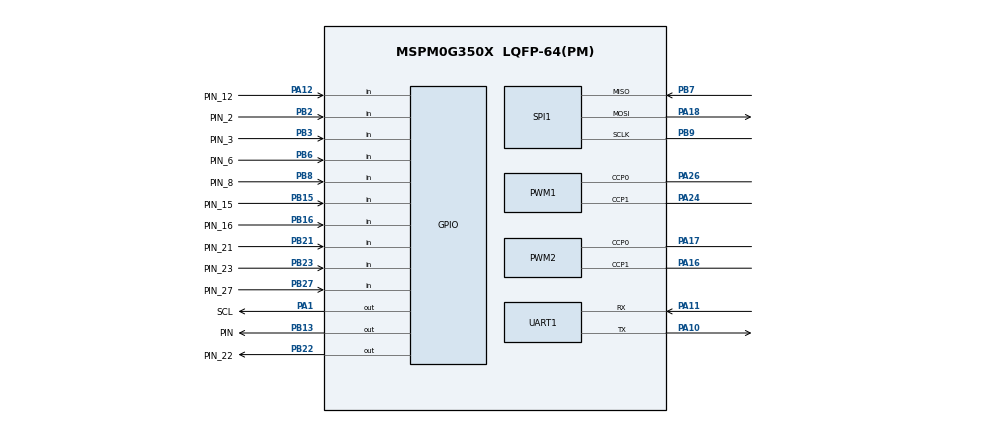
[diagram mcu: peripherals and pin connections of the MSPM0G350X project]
/**
 * @cliArgs --device "MSPM0G350X" --part "Default" --package "LQFP-64(PM)" --product "mspm0_sdk@2.02.00.05"
 * @versions {"tool":"1.21.1+3772"}
 */

/**
 * Import the modules used in this configuration.
 */
const GPIO   = scripting.addModule("/ti/driverlib/GPIO", {}, false);
const GPIO1  = GPIO.addInstance();
const GPIO2  = GPIO.addInstance();
const GPIO3  = GPIO.addInstance();
const GPIO4  = GPIO.addInstance();
const GPIO5  = GPIO.addInstance();
const GPIO6  = GPIO.addInstance();
const GPIO7  = GPIO.addInstance();
const GPIO8  = GPIO.addInstance();
const GPIO9  = GPIO.addInstance();
const GPIO10 = GPIO.addInstance();
const GPIO11 = GPIO.addInstance();
const GPIO12 = GPIO.addInstance();
const GPIO13 = GPIO.addInstance();
const PWM    = scripting.addModule("/ti/driverlib/PWM", {}, false);
const PWM1   = PWM.addInstance();
const PWM2   = PWM.addInstance();
const SPI    = scripting.addModule("/ti/driverlib/SPI", {}, false);
const SPI1   = SPI.addInstance();
const SYSCTL = scripting.addModule("/ti/driverlib/SYSCTL");
const TIMER  = scripting.addModule("/ti/driverlib/TIMER", {}, false);
const TIMER1 = TIMER.addInstance();
const UART   = scripting.addModule("/ti/driverlib/UART", {}, false);
const UART1  = UART.addInstance();

/**
 * Write custom configuration values to the imported modules.
 */
const gate7  = system.clockTree["MFCLKGATE"];
gate7.enable = true;

GPIO1.$name                              = "LED1";
GPIO1.port                               = "PORTB";
GPIO1.associatedPins[0].$name            = "PIN_22";
GPIO1.associatedPins[0].internalResistor = "PULL_DOWN";
GPIO1.associatedPins[0].assignedPin      = "22";
GPIO1.associatedPins[0].pin.$assign      = "PB22";

const Board = scripting.addModule("/ti/driverlib/Board", {}, false);

GPIO2.$name                              = "M0";
GPIO2.port                               = "PORTA";
GPIO2.associatedPins[0].direction        = "INPUT";
GPIO2.associatedPins[0].internalResistor = "PULL_DOWN";
GPIO2.associatedPins[0].$name            = "PIN_12";
GPIO2.associatedPins[0].assignedPin      = "12";
GPIO2.associatedPins[0].pin.$assign      = "PA12";

GPIO3.$name                              = "L1";
GPIO3.port                               = "PORTB";
GPIO3.associatedPins[0].direction        = "INPUT";
GPIO3.associatedPins[0].internalResistor = "PULL_DOWN";
GPIO3.associatedPins[0].$name            = "PIN_23";
GPIO3.associatedPins[0].assignedPin      = "23";
GPIO3.associatedPins[0].pin.$assign      = "PB23";

GPIO4.$name                              = "L2";
GPIO4.port                               = "PORTB";
GPIO4.associatedPins[0].direction        = "INPUT";
GPIO4.associatedPins[0].internalResistor = "PULL_DOWN";
GPIO4.associatedPins[0].$name            = "PIN_27";
GPIO4.associatedPins[0].assignedPin      = "27";
GPIO4.associatedPins[0].pin.$assign      = "PB27";

GPIO5.$name                              = "R1";
GPIO5.port                               = "PORTB";
GPIO5.associatedPins[0].direction        = "INPUT";
GPIO5.associatedPins[0].internalResistor = "PULL_DOWN";
GPIO5.associatedPins[0].$name            = "PIN_8";
GPIO5.associatedPins[0].assignedPin      = "8";
GPIO5.associatedPins[0].pin.$assign      = "PB8";

GPIO6.$name                              = "R2";
GPIO6.port                               = "PORTB";
GPIO6.associatedPins[0].direction        = "INPUT";
GPIO6.associatedPins[0].internalResistor = "PULL_DOWN";
GPIO6.associatedPins[0].$name            = "PIN_6";
GPIO6.associatedPins[0].assignedPin      = "6";
GPIO6.associatedPins[0].pin.$assign      = "PB6";

GPIO7.port                               = "PORTB";
GPIO7.$name                              = "KEY_4";
GPIO7.associatedPins[0].internalResistor = "PULL_UP";
GPIO7.associatedPins[0].direction        = "INPUT";
GPIO7.associatedPins[0].$name            = "PIN_3";
GPIO7.associatedPins[0].assignedPin      = "3";
GPIO7.associatedPins[0].pin.$assign      = "PB3";

GPIO8.port                               = "PORTB";
GPIO8.$name                              = "KEY_3";
GPIO8.associatedPins[0].internalResistor = "PULL_UP";
GPIO8.associatedPins[0].direction        = "INPUT";
GPIO8.associatedPins[0].$name            = "PIN_2";
GPIO8.associatedPins[0].assignedPin      = "2";
GPIO8.associatedPins[0].pin.$assign      = "PB2";

GPIO9.port                               = "PORTB";
GPIO9.$name                              = "KEY_2";
GPIO9.associatedPins[0].internalResistor = "PULL_UP";
GPIO9.associatedPins[0].direction        = "INPUT";
GPIO9.associatedPins[0].$name            = "PIN_16";
GPIO9.associatedPins[0].assignedPin      = "16";
GPIO9.associatedPins[0].pin.$assign      = "PB16";

GPIO10.port                               = "PORTB";
GPIO10.$name                              = "KEY_1";
GPIO10.associatedPins[0].direction        = "INPUT";
GPIO10.associatedPins[0].internalResistor = "PULL_UP";
GPIO10.associatedPins[0].$name            = "PIN_15";
GPIO10.associatedPins[0].assignedPin      = "15";
GPIO10.associatedPins[0].pin.$assign      = "PB15";

GPIO11.$name                              = "KEY_5";
GPIO11.port                               = "PORTB";
GPIO11.associatedPins[0].$name            = "PIN_21";
GPIO11.associatedPins[0].assignedPin      = "21";
GPIO11.associatedPins[0].internalResistor = "PULL_UP";
GPIO11.associatedPins[0].direction        = "INPUT";
GPIO11.associatedPins[0].pin.$assign      = "PB21";

GPIO12.$name                          = "I2C";
GPIO12.associatedPins.create(2);
GPIO12.associatedPins[0].$name        = "SDA";
GPIO12.associatedPins[0].initialValue = "SET";
GPIO12.associatedPins[0].assignedPin  = "0";
GPIO12.associatedPins[0].assignedPort = "PORTA";
GPIO12.associatedPins[1].$name        = "SCL";
GPIO12.associatedPins[1].initialValue = "SET";
GPIO12.associatedPins[1].assignedPort = "PORTA";
GPIO12.associatedPins[1].assignedPin  = "1";
GPIO12.associatedPins[1].pin.$assign  = "PA1";

GPIO13.$name                          = "CS";
GPIO13.associatedPins[0].$name        = "PIN";
GPIO13.associatedPins[0].assignedPort = "PORTB";
GPIO13.associatedPins[0].pin.$assign  = "PB13";

PWM1.clockDivider                       = 8;
PWM1.timerStartTimer                    = true;
PWM1.$name                              = "Motor_A";
PWM1.timerCount                         = 200;
PWM1.clockPrescale                      = 2;
PWM1.pwmMode                            = "CENTER_ALIGN";
PWM1.peripheral.$assign                 = "TIMG7";
PWM1.peripheral.ccp0Pin.$assign         = "PA26";
PWM1.peripheral.ccp1Pin.$assign         = "PA24";
PWM1.PWM_CHANNEL_0.$name                = "ti_driverlib_pwm_PWMTimerCC4";
PWM1.PWM_CHANNEL_1.$name                = "ti_driverlib_pwm_PWMTimerCC5";
PWM1.ccp0PinConfig.direction            = scripting.forceWrite("OUTPUT");
PWM1.ccp0PinConfig.hideOutputInversion  = scripting.forceWrite(false);
PWM1.ccp0PinConfig.onlyInternalResistor = scripting.forceWrite(false);
PWM1.ccp0PinConfig.passedPeripheralType = scripting.forceWrite("Digital");
PWM1.ccp0PinConfig.$name                = "ti_driverlib_gpio_GPIOPinGeneric6";
PWM1.ccp1PinConfig.direction            = scripting.forceWrite("OUTPUT");
PWM1.ccp1PinConfig.hideOutputInversion  = scripting.forceWrite(false);
PWM1.ccp1PinConfig.onlyInternalResistor = scripting.forceWrite(false);
PWM1.ccp1PinConfig.passedPeripheralType = scripting.forceWrite("Digital");
PWM1.ccp1PinConfig.$name                = "ti_driverlib_gpio_GPIOPinGeneric7";

PWM2.timerCount                         = 200;
PWM2.clockDivider                       = 8;
PWM2.timerStartTimer                    = true;
PWM2.$name                              = "Motor_B";
PWM2.pwmMode                            = "CENTER_ALIGN";
PWM2.clockPrescale                      = 2;
PWM2.peripheral.$assign                 = "TIMA1";
PWM2.peripheral.ccp0Pin.$assign         = "PA17";
PWM2.peripheral.ccp1Pin.$assign         = "PA16";
PWM2.PWM_CHANNEL_0.$name                = "ti_driverlib_pwm_PWMTimerCC0";
PWM2.PWM_CHANNEL_1.$name                = "ti_driverlib_pwm_PWMTimerCC1";
PWM2.ccp0PinConfig.$name                = "ti_driverlib_gpio_GPIOPinGeneric2";
PWM2.ccp0PinConfig.direction            = scripting.forceWrite("OUTPUT");
PWM2.ccp0PinConfig.hideOutputInversion  = scripting.forceWrite(false);
PWM2.ccp0PinConfig.onlyInternalResistor = scripting.forceWrite(false);
PWM2.ccp0PinConfig.passedPeripheralType = scripting.forceWrite("Digital");
PWM2.ccp1PinConfig.$name                = "ti_driverlib_gpio_GPIOPinGeneric3";
PWM2.ccp1PinConfig.direction            = scripting.forceWrite("OUTPUT");
PWM2.ccp1PinConfig.hideOutputInversion  = scripting.forceWrite(false);
PWM2.ccp1PinConfig.onlyInternalResistor = scripting.forceWrite(false);
PWM2.ccp1PinConfig.passedPeripheralType = scripting.forceWrite("Digital");

SPI1.$name                              = "SPI";
SPI1.targetBitRate                      = 16000000;
SPI1.frameFormat                        = "MOTO3";
SPI1.peripheral.$assign                 = "SPI1";
SPI1.peripheral.sclkPin.$assign         = "PB9";
SPI1.peripheral.mosiPin.$assign         = "PA18";
SPI1.peripheral.misoPin.$assign         = "PB7";
SPI1.sclkPinConfig.$name                = "ti_driverlib_gpio_GPIOPinGeneric4";
SPI1.sclkPinConfig.direction            = scripting.forceWrite("OUTPUT");
SPI1.sclkPinConfig.onlyInternalResistor = scripting.forceWrite(false);
SPI1.sclkPinConfig.passedPeripheralType = scripting.forceWrite("Digital");
SPI1.mosiPinConfig.$name                = "ti_driverlib_gpio_GPIOPinGeneric5";
SPI1.mosiPinConfig.direction            = scripting.forceWrite("OUTPUT");
SPI1.mosiPinConfig.hideOutputInversion  = scripting.forceWrite(false);
SPI1.mosiPinConfig.onlyInternalResistor = scripting.forceWrite(false);
SPI1.mosiPinConfig.passedPeripheralType = scripting.forceWrite("Digital");
SPI1.misoPinConfig.onlyInternalResistor = scripting.forceWrite(false);
SPI1.misoPinConfig.passedPeripheralType = scripting.forceWrite("Digital");
SPI1.misoPinConfig.$name                = "ti_driverlib_gpio_GPIOPinGeneric8";

SYSCTL.forceDefaultClkConfig = true;
SYSCTL.clockTreeEn           = true;

TIMER1.$name              = "TIMER_0";
TIMER1.timerClkDiv        = 8;
TIMER1.timerClkPrescale   = 100;
TIMER1.timerMode          = "PERIODIC";
TIMER1.interrupts         = ["ZERO"];
TIMER1.timerStartTimer    = true;
TIMER1.timerPeriod        = "5ms";
TIMER1.peripheral.$assign = "TIMA0";

UART1.$name                    = "UART_0";
UART1.targetBaudRate           = 115200;
UART1.uartClkSrc               = "MFCLK";
UART1.enabledInterrupts        = ["RX"];
UART1.peripheral.$assign       = "UART0";
UART1.peripheral.rxPin.$assign = "PA11";
UART1.peripheral.txPin.$assign = "PA10";
UART1.txPinConfig.$name        = "ti_driverlib_gpio_GPIOPinGeneric0";
UART1.rxPinConfig.$name        = "ti_driverlib_gpio_GPIOPinGeneric1";

/**
 * Pinmux solution for unlocked pins/peripherals. This ensures that minor changes to the automatic solver in a future
 * version of the tool will not impact the pinmux you originally saw.  These lines can be completely deleted in order to
 * re-solve from scratch.
 */
Board.peripheral.$suggestSolution             = "DEBUGSS";
Board.peripheral.swclkPin.$suggestSolution    = "PA20";
Board.peripheral.swdioPin.$suggestSolution    = "PA19";
GPIO12.associatedPins[0].pin.$suggestSolution = "PA0";
